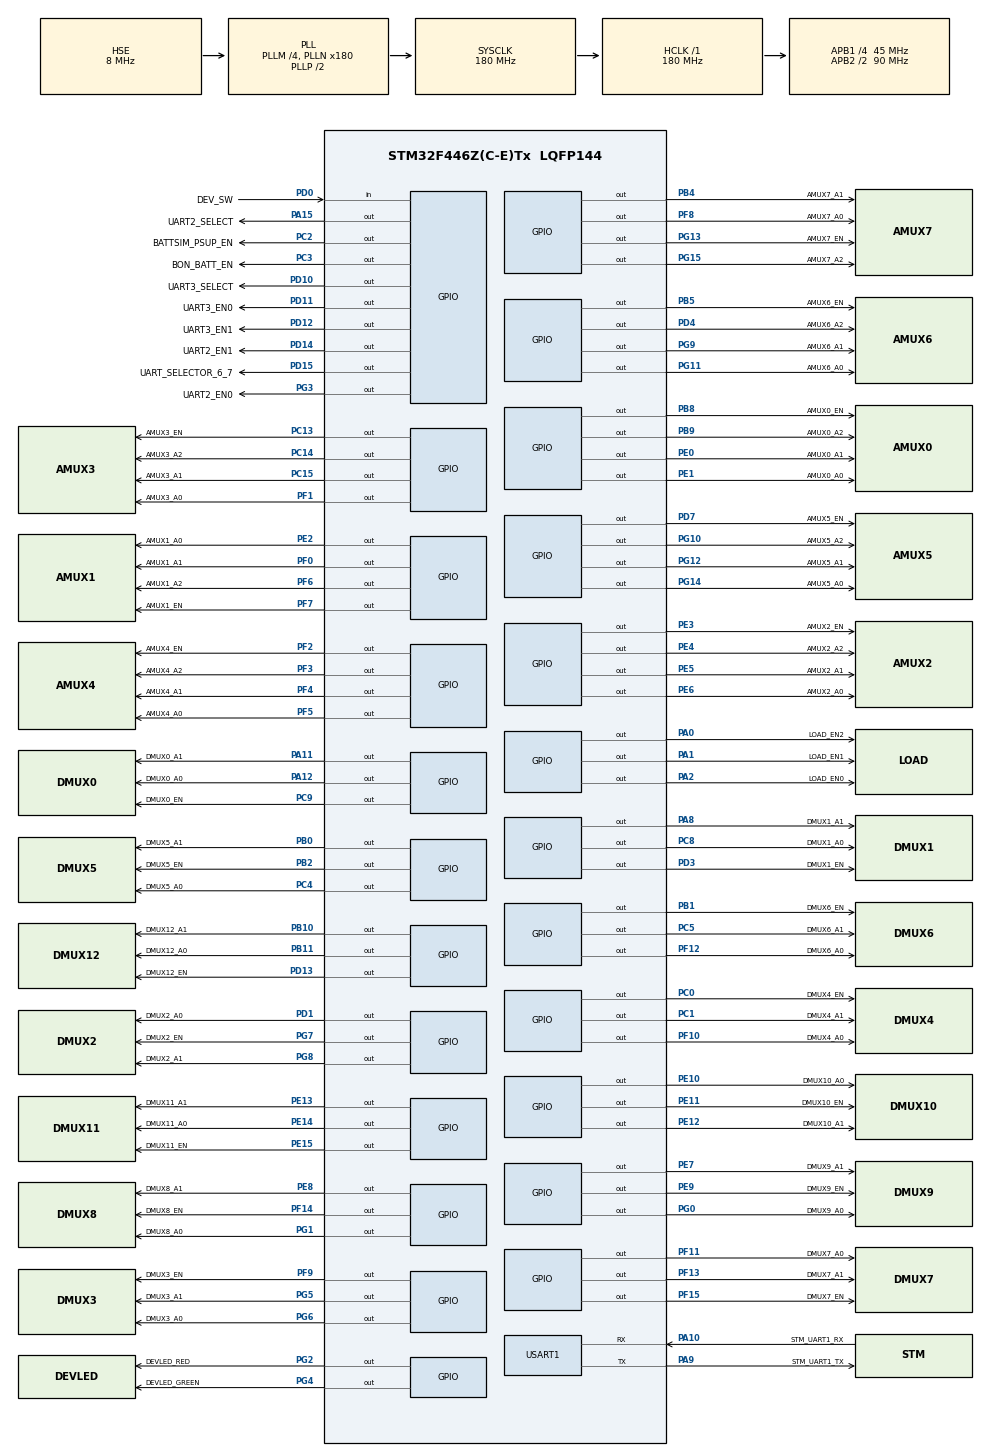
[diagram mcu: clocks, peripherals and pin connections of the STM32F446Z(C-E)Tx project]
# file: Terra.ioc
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Mcu.Family=STM32F4
Mcu.Name=STM32F446Z(C-E)Tx
Mcu.Package=LQFP144
NVIC.PriorityGroup=NVIC_PRIORITYGROUP_4
NVIC.TIM1_UP_TIM10_IRQn=true\:15\:0\:false\:false\:true\:false\:true\:true
NVIC.TimeBase=TIM1_UP_TIM10_IRQn
NVIC.TimeBaseIP=TIM1
PA0-WKUP.GPIO_Label=LOAD_EN2
PA0-WKUP.Signal=GPIO_Output
PA1.GPIO_Label=LOAD_EN1
PA1.Signal=GPIO_Output
PA10.GPIO_Label=STM_UART1_RX
PA10.Mode=Asynchronous
PA10.Signal=USART1_RX
PA11.GPIO_Label=DMUX0_A1
PA11.Signal=GPIO_Output
PA12.GPIO_Label=DMUX0_A0
PA12.Signal=GPIO_Output
PA13.Signal=SYS_JTMS-SWDIO
PA14.Signal=SYS_JTCK-SWCLK
PA15.GPIO_Label=UART2_SELECT
PA15.Signal=GPIO_Output
PA2.GPIO_Label=LOAD_EN0
PA2.Signal=GPIO_Output
PA4.GPIO_Label=SPI1_CS
PA4.Signal=SPI1_NSS
PA5.GPIO_Label=SPI1_SCLK
PA5.Signal=SPI1_SCK
PA6.Signal=SPI1_MISO
PA7.Signal=SPI1_MOSI
PA8.GPIO_Label=DMUX1_A1
PA8.Signal=GPIO_Output
PA9.GPIO_Label=STM_UART1_TX
PA9.Mode=Asynchronous
PA9.Signal=USART1_TX
PB0.GPIO_Label=DMUX5_A1
PB0.Signal=GPIO_Output
PB1.GPIO_Label=DMUX6_EN
PB1.Signal=GPIO_Output
PB10.GPIO_Label=DMUX12_A1
PB10.Signal=GPIO_Output
PB11.GPIO_Label=DMUX12_A0
PB11.Signal=GPIO_Output
PB12.GPIO_Label=SPI2_CS
PB12.Signal=SPI2_NSS
PB13.GPIO_Label=SPI2_SCLK
PB13.Signal=SPI2_SCK
PB14.Signal=SPI2_MISO
PB15.Signal=SPI2_MOSI
PB2.GPIO_Label=DMUX5_EN
PB2.Signal=GPIO_Output
PB3.Signal=SYS_JTDO-SWO
PB4.GPIO_Label=AMUX7_A1
PB4.Signal=GPIO_Output
PB5.GPIO_Label=AMUX6_EN
PB5.Signal=GPIO_Output
PB6.Signal=I2C1_SCL
PB7.Signal=I2C1_SDA
PB8.GPIO_Label=AMUX0_EN
PB8.Signal=GPIO_Output
PB9.GPIO_Label=AMUX0_A2
PB9.Signal=GPIO_Output
PC0.GPIO_Label=DMUX4_EN
PC0.Signal=GPIO_Output
PC1.GPIO_Label=DMUX4_A1
PC1.Signal=GPIO_Output
PC10.GPIO_Label=STM_UART4_TX
PC10.Signal=UART4_TX
PC11.GPIO_Label=STM_UART4_RX
PC11.Signal=UART4_RX
PC12.GPIO_Label=STM_UART5_TX
PC12.Signal=UART5_TX
PC13.GPIO_Label=AMUX3_EN
PC13.Signal=GPIO_Output
PC14-OSC32_IN.GPIO_Label=AMUX3_A2
PC14-OSC32_IN.Signal=GPIO_Output
PC15-OSC32_OUT.GPIO_Label=AMUX3_A1
PC15-OSC32_OUT.Signal=GPIO_Output
PC2.GPIO_Label=BATTSIM_PSUP_EN
PC2.Signal=GPIO_Output
PC3.GPIO_Label=BON_BATT_EN
PC3.Signal=GPIO_Output
PC4.GPIO_Label=DMUX5_A0
PC4.Signal=GPIO_Output
PC5.GPIO_Label=DMUX6_A1
PC5.Signal=GPIO_Output
PC6.GPIO_Label=STM_UART6_TX
PC6.Signal=USART6_TX
PC7.GPIO_Label=STM_UART6_RX
PC7.Signal=USART6_RX
PC8.GPIO_Label=DMUX1_A0
PC8.Signal=GPIO_Output
PC9.GPIO_Label=DMUX0_EN
PC9.Signal=GPIO_Output
PD0.GPIO_Label=DEV_SW
PD0.Signal=GPIO_Input
PD1.GPIO_Label=DMUX2_A0
PD1.Signal=GPIO_Output
PD10.GPIO_Label=UART3_SELECT
PD10.Signal=GPIO_Output
PD11.GPIO_Label=UART3_EN0
PD11.Signal=GPIO_Output
PD12.GPIO_Label=UART3_EN1
PD12.Signal=GPIO_Output
PD13.GPIO_Label=DMUX12_EN
PD13.Signal=GPIO_Output
PD14.GPIO_Label=UART2_EN1
PD14.Signal=GPIO_Output
PD15.GPIO_Label=UART_SELECTOR_6_7
PD15.Signal=GPIO_Output
PD2.GPIO_Label=STM_UART5_RX
PD2.Signal=UART5_RX
PD3.GPIO_Label=DMUX1_EN
PD3.Signal=GPIO_Output
PD4.GPIO_Label=AMUX6_A2
PD4.Signal=GPIO_Output
PD5.GPIO_Label=STM_UART2_TX
PD5.Signal=USART2_TX
PD6.GPIO_Label=STM_UART2_RX
PD6.Signal=USART2_RX
PD7.GPIO_Label=AMUX5_EN
PD7.Signal=GPIO_Output
PD8.GPIO_Label=STM_UART3_TX
PD8.Signal=USART3_TX
PD9.GPIO_Label=STM_UART3_RX
PD9.Signal=USART3_RX
PE0.GPIO_Label=AMUX0_A1
PE0.Signal=GPIO_Output
PE1.GPIO_Label=AMUX0_A0
PE1.Signal=GPIO_Output
PE10.GPIO_Label=DMUX10_A0
PE10.Signal=GPIO_Output
PE11.GPIO_Label=DMUX10_EN
PE11.Signal=GPIO_Output
PE12.GPIO_Label=DMUX10_A1
PE12.Signal=GPIO_Output
PE13.GPIO_Label=DMUX11_A1
PE13.Signal=GPIO_Output
PE14.GPIO_Label=DMUX11_A0
PE14.Signal=GPIO_Output
PE15.GPIO_Label=DMUX11_EN
PE15.Signal=GPIO_Output
PE2.GPIO_Label=AMUX1_A0
PE2.Signal=GPIO_Output
PE3.GPIO_Label=AMUX2_EN
PE3.Signal=GPIO_Output
PE4.GPIO_Label=AMUX2_A2
PE4.Signal=GPIO_Output
PE5.GPIO_Label=AMUX2_A1
PE5.Signal=GPIO_Output
PE6.GPIO_Label=AMUX2_A0
PE6.Signal=GPIO_Output
PE7.GPIO_Label=DMUX9_A1
PE7.Signal=GPIO_Output
PE8.GPIO_Label=DMUX8_A1
PE8.Signal=GPIO_Output
PE9.GPIO_Label=DMUX9_EN
PE9.Signal=GPIO_Output
PF0.GPIO_Label=AMUX1_A1
PF0.Signal=GPIO_Output
PF1.GPIO_Label=AMUX3_A0
PF1.Signal=GPIO_Output
PF10.GPIO_Label=DMUX4_A0
PF10.Signal=GPIO_Output
PF11.GPIO_Label=DMUX7_A0
PF11.Signal=GPIO_Output
PF12.GPIO_Label=DMUX6_A0
PF12.Signal=GPIO_Output
PF13.GPIO_Label=DMUX7_A1
PF13.Signal=GPIO_Output
PF14.GPIO_Label=DMUX8_EN
PF14.Signal=GPIO_Output
PF15.GPIO_Label=DMUX7_EN
PF15.Signal=GPIO_Output
PF2.GPIO_Label=AMUX4_EN
PF2.Signal=GPIO_Output
PF3.GPIO_Label=AMUX4_A2
PF3.Signal=GPIO_Output
PF4.GPIO_Label=AMUX4_A1
PF4.Signal=GPIO_Output
PF5.GPIO_Label=AMUX4_A0
PF5.Signal=GPIO_Output
PF6.GPIO_Label=AMUX1_A2
PF6.Signal=GPIO_Output
PF7.GPIO_Label=AMUX1_EN
PF7.Signal=GPIO_Output
PF8.GPIO_Label=AMUX7_A0
PF8.Signal=GPIO_Output
PF9.GPIO_Label=DMUX3_EN
PF9.Signal=GPIO_Output
PG0.GPIO_Label=DMUX9_A0
PG0.Signal=GPIO_Output
PG1.GPIO_Label=DMUX8_A0
PG1.Signal=GPIO_Output
PG10.GPIO_Label=AMUX5_A2
PG10.Signal=GPIO_Output
PG11.GPIO_Label=AMUX6_A0
PG11.Signal=GPIO_Output
PG12.GPIO_Label=AMUX5_A1
PG12.Signal=GPIO_Output
PG13.GPIO_Label=AMUX7_EN
PG13.Signal=GPIO_Output
PG14.GPIO_Label=AMUX5_A0
PG14.Signal=GPIO_Output
PG15.GPIO_Label=AMUX7_A2
PG15.Signal=GPIO_Output
PG2.GPIO_Label=DEVLED_RED
PG2.Signal=GPIO_Output
PG3.GPIO_Label=UART2_EN0
PG3.Signal=GPIO_Output
PG4.GPIO_Label=DEVLED_GREEN
PG4.Signal=GPIO_Output
PG5.GPIO_Label=DMUX3_A1
PG5.Signal=GPIO_Output
PG6.GPIO_Label=DMUX3_A0
PG6.Signal=GPIO_Output
PG7.GPIO_Label=DMUX2_EN
PG7.Signal=GPIO_Output
PG8.GPIO_Label=DMUX2_A1
PG8.Signal=GPIO_Output
PG9.GPIO_Label=AMUX6_A1
PG9.Signal=GPIO_Output
PH0-OSC_IN.Mode=HSE-External-Oscillator
PH0-OSC_IN.Signal=RCC_OSC_IN
PH1-OSC_OUT.Mode=HSE-External-Oscillator
PH1-OSC_OUT.Signal=RCC_OSC_OUT
ProjectManager.HeapSize=0x200
ProjectManager.StackSize=0x400
ProjectManager.TargetToolchain=STM32CubeIDE
RCC.AHBFreq_Value=180000000
RCC.APB1CLKDivider=RCC_HCLK_DIV4
RCC.APB1Freq_Value=45000000
RCC.APB1TimFreq_Value=90000000
RCC.APB2CLKDivider=RCC_HCLK_DIV2
RCC.APB2Freq_Value=90000000
RCC.APB2TimFreq_Value=180000000
RCC.CortexFreq_Value=180000000
RCC.HCLKFreq_Value=180000000
RCC.HSE_VALUE=8000000
RCC.PLLI2SM=2
RCC.PLLI2SN=50
RCC.PLLM=4
RCC.PLLN=180
RCC.PLLSAIM=2
RCC.PLLSourceVirtual=RCC_PLLSOURCE_HSE
RCC.SYSCLKFreq_VALUE=180000000
RCC.SYSCLKSource=RCC_SYSCLKSOURCE_PLLCLK
RCC.USBFreq_Value=180000000
RCC.VCOOutputFreq_Value=360000000
USART1.VirtualMode=VM_ASYNC
VP_CRC_VS_CRC.Mode=CRC_Activate
VP_SYS_VS_tim1.Mode=TIM1
board=custom

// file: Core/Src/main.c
/* USER CODE BEGIN Header */
/**
  ******************************************************************************
  * @file           : main.c
  * @brief          : Main program body
  ******************************************************************************
  * @attention
  *
  * Copyright (c) 2025 STMicroelectronics.
  * All rights reserved.
  *
  * This software is licensed under terms that can be found in the LICENSE file
  * in the root directory of this software component.
  * If no LICENSE file comes with this software, it is provided AS-IS.
  *
  ******************************************************************************
  */
/* USER CODE END Header */
#include "main.h"
#include "crc.h"
#include "usart.h"
#include "gpio.h"

/* USER CODE BEGIN Includes */
#include "amux.h"
#include "dmux.h"
#include "processCommand.h"
#include "uart_handler.h"
#include <string.h>
#include <stdio.h>
/* USER CODE END Includes */

/* USER CODE BEGIN PV */
  int Amux_ID = 6;
  int Amux_InSelect = 0;
  int Dmux_ID = 5; // Example demultiplexer ID
  int Dmux_InSelect = 0;
/* USER CODE END PV */

void SystemClock_Config(void);

int main(void)
{

  /* MCU Configuration--------------------------------------------------------*/

  /* Reset of all peripherals, Initializes the Flash interface and the Systick. */
  HAL_Init();

  /* Configure the system clock */
  SystemClock_Config();

  /* USER CODE BEGIN SysInit */
  //huart1.Init.RXFIFOThreshold = UART_RXFIFO_THRESHOLD_1_8; // Set threshold to 1/8 of the FIFO size
  /* USER CODE END SysInit */

  /* Initialize all configured peripherals */
  MX_GPIO_Init();
  MX_USART1_UART_Init();
  MX_CRC_Init();
  /* USER CODE BEGIN 2 */
 /*
  uint8_t txData[] = "Testing VCP!";
   uint8_t rxData[4];

   */
  /* USER CODE END 2 */

  /* Infinite loop */
  /* USER CODE BEGIN WHILE */
       uint8_t txData[] = "Testing VCP!";

          HAL_UART_Transmit(&huart1, txData, sizeof(txData), HAL_MAX_DELAY);
       HAL_GPIO_TogglePin(GPIOG, DEVLED_RED_Pin);
       HAL_GPIO_TogglePin(GPIOG, DEVLED_GREEN_Pin);
  while (1)
  {

	  UART_Receive_Handler();
	  /*

      */

    /* USER CODE END WHILE */

  }
}

void SystemClock_Config(void)
{
  RCC_OscInitTypeDef RCC_OscInitStruct = {0};
  RCC_ClkInitTypeDef RCC_ClkInitStruct = {0};

  /** Configure the main internal regulator output voltage
  */
  __HAL_RCC_PWR_CLK_ENABLE();
  __HAL_PWR_VOLTAGESCALING_CONFIG(PWR_REGULATOR_VOLTAGE_SCALE1);

  /** Initializes the RCC Oscillators according to the specified parameters
  * in the RCC_OscInitTypeDef structure.
  */
  RCC_OscInitStruct.OscillatorType = RCC_OSCILLATORTYPE_HSE;
  RCC_OscInitStruct.HSEState = RCC_HSE_ON;
  RCC_OscInitStruct.PLL.PLLState = RCC_PLL_ON;
  RCC_OscInitStruct.PLL.PLLSource = RCC_PLLSOURCE_HSE;
  RCC_OscInitStruct.PLL.PLLM = 4;
  RCC_OscInitStruct.PLL.PLLN = 180;
  RCC_OscInitStruct.PLL.PLLP = RCC_PLLP_DIV2;
  RCC_OscInitStruct.PLL.PLLQ = 2;
  RCC_OscInitStruct.PLL.PLLR = 2;
  if (HAL_RCC_OscConfig(&RCC_OscInitStruct) != HAL_OK)
  {
    Error_Handler();
  }

  /** Activate the Over-Drive mode
  */
  if (HAL_PWREx_EnableOverDrive() != HAL_OK)
  {
    Error_Handler();
  }

  /** Initializes the CPU, AHB and APB buses clocks
  */
  RCC_ClkInitStruct.ClockType = RCC_CLOCKTYPE_HCLK|RCC_CLOCKTYPE_SYSCLK
                              |RCC_CLOCKTYPE_PCLK1|RCC_CLOCKTYPE_PCLK2;
  RCC_ClkInitStruct.SYSCLKSource = RCC_SYSCLKSOURCE_PLLCLK;
  RCC_ClkInitStruct.AHBCLKDivider = RCC_SYSCLK_DIV1;
  RCC_ClkInitStruct.APB1CLKDivider = RCC_HCLK_DIV4;
  RCC_ClkInitStruct.APB2CLKDivider = RCC_HCLK_DIV2;

  if (HAL_RCC_ClockConfig(&RCC_ClkInitStruct, FLASH_LATENCY_5) != HAL_OK)
  {
    Error_Handler();
  }
}

void HAL_TIM_PeriodElapsedCallback(TIM_HandleTypeDef *htim)
{
  if (htim->Instance == TIM1) {
    HAL_IncTick();
  }
}

void Error_Handler(void)
{
  __disable_irq();
  while (1)
  {
  }
}
